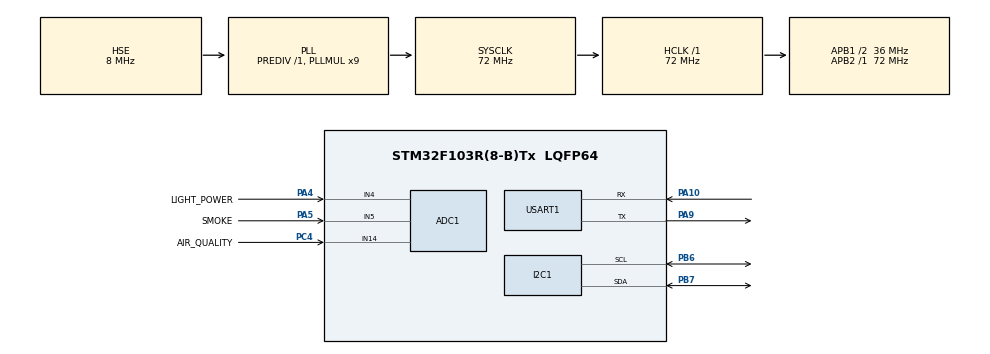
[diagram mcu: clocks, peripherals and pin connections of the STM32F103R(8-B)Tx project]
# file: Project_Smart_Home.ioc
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ADC1.Channel-0\#ChannelRegularConversion=ADC_CHANNEL_4
ADC1.Channel-1\#ChannelRegularConversion=ADC_CHANNEL_5
ADC1.Channel-2\#ChannelRegularConversion=ADC_CHANNEL_14
ADC1.DiscontinuousConvMode=ENABLE
ADC1.NbrOfConversion=3
ADC1.NbrOfConversionFlag=1
ADC1.Rank-0\#ChannelRegularConversion=1
ADC1.Rank-1\#ChannelRegularConversion=2
ADC1.Rank-2\#ChannelRegularConversion=3
ADC1.SamplingTime-0\#ChannelRegularConversion=ADC_SAMPLETIME_55CYCLES_5
ADC1.SamplingTime-1\#ChannelRegularConversion=ADC_SAMPLETIME_55CYCLES_5
ADC1.SamplingTime-2\#ChannelRegularConversion=ADC_SAMPLETIME_55CYCLES_5
ADC1.master=1
I2C1.I2C_Mode=I2C_Fast
Mcu.Family=STM32F1
Mcu.Name=STM32F103R(8-B)Tx
Mcu.Package=LQFP64
NVIC.PriorityGroup=NVIC_PRIORITYGROUP_4
PA10.Mode=Asynchronous
PA10.Signal=USART1_RX
PA4.GPIO_Label=LIGHT_POWER
PA4.Signal=ADCx_IN4
PA5.GPIO_Label=SMOKE
PA5.Signal=ADCx_IN5
PA9.Mode=Asynchronous
PA9.Signal=USART1_TX
PB6.Mode=I2C
PB6.Signal=I2C1_SCL
PB7.Mode=I2C
PB7.Signal=I2C1_SDA
PC4.GPIO_Label=AIR_QUALITY
PC4.Signal=ADCx_IN14
PD0-OSC_IN.Mode=HSE-External-Oscillator
PD0-OSC_IN.Signal=RCC_OSC_IN
PD1-OSC_OUT.Mode=HSE-External-Oscillator
PD1-OSC_OUT.Signal=RCC_OSC_OUT
ProjectManager.HeapSize=0x200
ProjectManager.StackSize=0x400
ProjectManager.TargetToolchain=MDK-ARM V5.32
RCC.ADCPresc=RCC_ADCPCLK2_DIV6
RCC.AHBFreq_Value=72000000
RCC.APB1CLKDivider=RCC_HCLK_DIV2
RCC.APB1Freq_Value=36000000
RCC.APB1TimFreq_Value=72000000
RCC.APB2Freq_Value=72000000
RCC.APB2TimFreq_Value=72000000
RCC.HCLKFreq_Value=72000000
RCC.PLLMUL=RCC_PLL_MUL9
RCC.PLLSourceVirtual=RCC_PLLSOURCE_HSE
RCC.SYSCLKFreq_VALUE=72000000
RCC.SYSCLKSource=RCC_SYSCLKSOURCE_PLLCLK
RCC.USBFreq_Value=72000000
SH.ADCx_IN14.0=ADC1_IN14,IN14
SH.ADCx_IN4.0=ADC1_IN4,IN4
SH.ADCx_IN5.0=ADC1_IN5,IN5
TIM2.Prescaler=71
USART1.VirtualMode=VM_ASYNC
VP_SYS_VS_ND.Mode=No_Debug
VP_TIM2_VS_ClockSourceINT.Mode=Internal
board=custom

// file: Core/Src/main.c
/* USER CODE BEGIN Header */
/**
  ******************************************************************************
  * @file           : main.c
  * @brief          : Main program body
  ******************************************************************************
  * @attention
  *
  * Copyright (c) 2026 STMicroelectronics.
  * All rights reserved.
  *
  * This software is licensed under terms that can be found in the LICENSE file
  * in the root directory of this software component.
  * If no LICENSE file comes with this software, it is provided AS-IS.
  *
  ******************************************************************************
  */
/* USER CODE END Header */
#include "main.h"
#include "adc.h"
#include "i2c.h"
#include "tim.h"
#include "usart.h"
#include "gpio.h"

/* USER CODE BEGIN Includes */
#include "detection.h"
#include "ds18b20.h"
#include <stdio.h>
/* USER CODE END Includes */

void SystemClock_Config(void);

int main(void)
{

  /* MCU Configuration--------------------------------------------------------*/

  /* Reset of all peripherals, Initializes the Flash interface and the Systick. */
  HAL_Init();

  /* Configure the system clock */
  SystemClock_Config();

  /* USER CODE BEGIN SysInit */
	DS18B20_Init();
  /* USER CODE END SysInit */

  /* Initialize all configured peripherals */
  MX_GPIO_Init();
  MX_ADC1_Init();
  MX_USART1_UART_Init();
  MX_TIM2_Init();
  MX_I2C1_Init();
  /* USER CODE BEGIN 2 */
	HAL_ADCEx_Calibration_Start(&hadc1);
	uint32_t data[3];
	uint8_t i = 0;
	float temper;
  /* USER CODE END 2 */

  /* Infinite loop */
  /* USER CODE BEGIN WHILE */
  while (1)
  {
		//采集ADC的数�?,测量光照强度,烟雾强度
		Detection_Init(data);
		for(i = 0; i < 3;i++)
		{
			printf("data[%d]--->%d\r\n",i,data[i]);
		}
		DS18B20_Get_Data(&temper);
		printf("temper ----> %.4f\r\n",temper);

		HAL_Delay(2000);
    /* USER CODE END WHILE */

  }
}

void SystemClock_Config(void)
{
  RCC_OscInitTypeDef RCC_OscInitStruct = {0};
  RCC_ClkInitTypeDef RCC_ClkInitStruct = {0};
  RCC_PeriphCLKInitTypeDef PeriphClkInit = {0};

  /** Initializes the RCC Oscillators according to the specified parameters
  * in the RCC_OscInitTypeDef structure.
  */
  RCC_OscInitStruct.OscillatorType = RCC_OSCILLATORTYPE_HSE;
  RCC_OscInitStruct.HSEState = RCC_HSE_ON;
  RCC_OscInitStruct.HSEPredivValue = RCC_HSE_PREDIV_DIV1;
  RCC_OscInitStruct.HSIState = RCC_HSI_ON;
  RCC_OscInitStruct.PLL.PLLState = RCC_PLL_ON;
  RCC_OscInitStruct.PLL.PLLSource = RCC_PLLSOURCE_HSE;
  RCC_OscInitStruct.PLL.PLLMUL = RCC_PLL_MUL9;
  if (HAL_RCC_OscConfig(&RCC_OscInitStruct) != HAL_OK)
  {
    Error_Handler();
  }

  /** Initializes the CPU, AHB and APB buses clocks
  */
  RCC_ClkInitStruct.ClockType = RCC_CLOCKTYPE_HCLK|RCC_CLOCKTYPE_SYSCLK
                              |RCC_CLOCKTYPE_PCLK1|RCC_CLOCKTYPE_PCLK2;
  RCC_ClkInitStruct.SYSCLKSource = RCC_SYSCLKSOURCE_PLLCLK;
  RCC_ClkInitStruct.AHBCLKDivider = RCC_SYSCLK_DIV1;
  RCC_ClkInitStruct.APB1CLKDivider = RCC_HCLK_DIV2;
  RCC_ClkInitStruct.APB2CLKDivider = RCC_HCLK_DIV1;

  if (HAL_RCC_ClockConfig(&RCC_ClkInitStruct, FLASH_LATENCY_2) != HAL_OK)
  {
    Error_Handler();
  }
  PeriphClkInit.PeriphClockSelection = RCC_PERIPHCLK_ADC;
  PeriphClkInit.AdcClockSelection = RCC_ADCPCLK2_DIV6;
  if (HAL_RCCEx_PeriphCLKConfig(&PeriphClkInit) != HAL_OK)
  {
    Error_Handler();
  }
}

void Error_Handler(void)
{
  __disable_irq();
  while (1)
  {
  }
}
